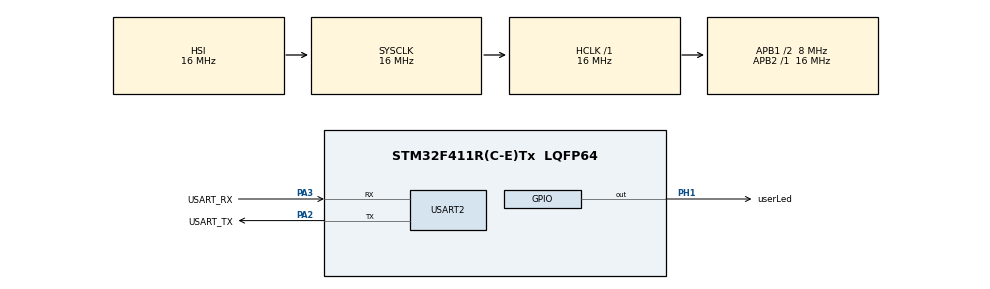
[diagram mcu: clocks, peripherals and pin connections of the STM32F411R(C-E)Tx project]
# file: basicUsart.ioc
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Mcu.Family=STM32F4
Mcu.Name=STM32F411R(C-E)Tx
Mcu.Package=LQFP64
NVIC.PriorityGroup=NVIC_PRIORITYGROUP_0
NVIC.TIM2_IRQn=true\:0\:0\:false\:false\:true\:true\:true\:true
NVIC.USART2_IRQn=true\:0\:0\:false\:false\:true\:true\:true\:true
PA13.GPIO_Label=TMS
PA13.Mode=Serial_Wire
PA13.Signal=SYS_JTMS-SWDIO
PA14.GPIO_Label=TCK
PA14.Mode=Serial_Wire
PA14.Signal=SYS_JTCK-SWCLK
PA2.GPIO_Label=USART_TX
PA2.Mode=Asynchronous
PA2.Signal=USART2_TX
PA3.GPIO_Label=USART_RX
PA3.Mode=Asynchronous
PA3.Signal=USART2_RX
PB3.GPIO_Label=SWO
PB3.Signal=SYS_JTDO-SWO
PH1\ -\ OSC_OUT.GPIO_Label=userLed
PH1\ -\ OSC_OUT.PinState=GPIO_PIN_SET
PH1\ -\ OSC_OUT.Signal=GPIO_Output
ProjectManager.HeapSize=0x200
ProjectManager.StackSize=0x400
ProjectManager.TargetToolchain=STM32CubeIDE
RCC.48MHZClocksFreq_Value=84000000
RCC.AHBFreq_Value=16000000
RCC.APB1CLKDivider=RCC_HCLK_DIV2
RCC.APB1Freq_Value=8000000
RCC.APB1TimFreq_Value=16000000
RCC.APB2Freq_Value=16000000
RCC.APB2TimFreq_Value=16000000
RCC.CortexFreq_Value=16000000
RCC.FLatency-AdvancedSettings=FLASH_LATENCY_0
RCC.HCLKFreq_Value=16000000
RCC.HSE_VALUE=8000000
RCC.HSI_VALUE=16000000
RCC.LSE_VALUE=32768
RCC.PLLN=336
RCC.PLLP=RCC_PLLP_DIV4
RCC.SYSCLKFreq_VALUE=16000000
RCC.VCOOutputFreq_Value=336000000
TIM2.Period=500-1
TIM2.Prescaler=16000-1
USART2.VirtualMode=VM_ASYNC
VP_TIM2_VS_ClockSourceINT.Mode=Internal
board=NUCLEO-F411RE

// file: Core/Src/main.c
/* USER CODE BEGIN Header */
/**
  ******************************************************************************
  * @file           : main.c
  * @brief          : Main program body
  ******************************************************************************
  * @attention
  *
  * Copyright (c) 2025 STMicroelectronics.
  * All rights reserved.
  *
  * This software is licensed under terms that can be found in the LICENSE file
  * in the root directory of this software component.
  * If no LICENSE file comes with this software, it is provided AS-IS.
  *
  ******************************************************************************
  */
/* USER CODE END Header */
#include "main.h"

/* USER CODE BEGIN Includes */
#include "stdint.h"
#include "stdio.h"
#include "string.h"
/* USER CODE END Includes */

TIM_HandleTypeDef htim2;

UART_HandleTypeDef huart2;

void SystemClock_Config(void);
static void MX_GPIO_Init(void);
static void MX_USART2_UART_Init(void);
static void MX_TIM2_Init(void);
/* USER CODE BEGIN PFP */
uint8_t contador = 0;
uint8_t bufferMsg[128] = {0};
uint8_t rx_buffer[100];
uint8_t rx_index = 0;
uint8_t rx_char = 0;
volatile uint8_t usart_flag = 0 ;
/* USER CODE END PFP */

int main(void)
{

  /* MCU Configuration--------------------------------------------------------*/

  /* Reset of all peripherals, Initializes the Flash interface and the Systick. */
  HAL_Init();

  /* Configure the system clock */
  SystemClock_Config();

  /* Initialize all configured peripherals */
  MX_GPIO_Init();
  MX_USART2_UART_Init();
  MX_TIM2_Init();
  /* USER CODE BEGIN 2 */
  HAL_TIM_Base_Start_IT(&htim2);
  HAL_UART_Receive_IT(&huart2,&rx_char,1);
  /* USER CODE END 2 */

  /* Infinite loop */
  /* USER CODE BEGIN WHILE */

  sprintf((char *)bufferMsg,"Prueba de sonido %u!! '\n'",contador);
  HAL_UART_Transmit(&huart2,bufferMsg,strlen((char *)bufferMsg),1000);
  __NOP();
  while (1)
  {
    /* USER CODE END WHILE */
	  if (usart_flag) {
		  sprintf((char *)bufferMsg,"Comando recibido %s\n",rx_buffer);
		  HAL_UART_Transmit(&huart2,bufferMsg,strlen((char * )bufferMsg),1000);
	      if (strncmp((char*)rx_buffer,"led=",4)==0){
	    	  int nuevo_delay = atoi((char*)&rx_buffer[4]);
	    	  __HAL_TIM_SET_AUTORELOAD(&htim2,nuevo_delay);
	          __HAL_TIM_SET_COUNTER(&htim2, 0);
	      }
	      // 4. ¡Limpio el buffer para el próximo comando!
	      memset(rx_buffer,0,sizeof(rx_buffer));

	      // 5. Bajo la bandera y sigo
	      usart_flag = 0;
	      }

  }
}

void SystemClock_Config(void)
{
  RCC_OscInitTypeDef RCC_OscInitStruct = {0};
  RCC_ClkInitTypeDef RCC_ClkInitStruct = {0};

  /** Configure the main internal regulator output voltage
  */
  __HAL_RCC_PWR_CLK_ENABLE();
  __HAL_PWR_VOLTAGESCALING_CONFIG(PWR_REGULATOR_VOLTAGE_SCALE1);

  /** Initializes the RCC Oscillators according to the specified parameters
  * in the RCC_OscInitTypeDef structure.
  */
  RCC_OscInitStruct.OscillatorType = RCC_OSCILLATORTYPE_HSI;
  RCC_OscInitStruct.HSIState = RCC_HSI_ON;
  RCC_OscInitStruct.HSICalibrationValue = RCC_HSICALIBRATION_DEFAULT;
  RCC_OscInitStruct.PLL.PLLState = RCC_PLL_NONE;
  if (HAL_RCC_OscConfig(&RCC_OscInitStruct) != HAL_OK)
  {
    Error_Handler();
  }

  /** Initializes the CPU, AHB and APB buses clocks
  */
  RCC_ClkInitStruct.ClockType = RCC_CLOCKTYPE_HCLK|RCC_CLOCKTYPE_SYSCLK
                              |RCC_CLOCKTYPE_PCLK1|RCC_CLOCKTYPE_PCLK2;
  RCC_ClkInitStruct.SYSCLKSource = RCC_SYSCLKSOURCE_HSI;
  RCC_ClkInitStruct.AHBCLKDivider = RCC_SYSCLK_DIV1;
  RCC_ClkInitStruct.APB1CLKDivider = RCC_HCLK_DIV2;
  RCC_ClkInitStruct.APB2CLKDivider = RCC_HCLK_DIV1;

  if (HAL_RCC_ClockConfig(&RCC_ClkInitStruct, FLASH_LATENCY_0) != HAL_OK)
  {
    Error_Handler();
  }
}

static void MX_TIM2_Init(void)
{

  TIM_ClockConfigTypeDef sClockSourceConfig = {0};
  TIM_MasterConfigTypeDef sMasterConfig = {0};

  htim2.Instance = TIM2;
  htim2.Init.Prescaler = 16000-1;
  htim2.Init.CounterMode = TIM_COUNTERMODE_UP;
  htim2.Init.Period = 500-1;
  htim2.Init.ClockDivision = TIM_CLOCKDIVISION_DIV1;
  htim2.Init.AutoReloadPreload = TIM_AUTORELOAD_PRELOAD_DISABLE;
  if (HAL_TIM_Base_Init(&htim2) != HAL_OK)
  {
    Error_Handler();
  }
  sClockSourceConfig.ClockSource = TIM_CLOCKSOURCE_INTERNAL;
  if (HAL_TIM_ConfigClockSource(&htim2, &sClockSourceConfig) != HAL_OK)
  {
    Error_Handler();
  }
  sMasterConfig.MasterOutputTrigger = TIM_TRGO_RESET;
  sMasterConfig.MasterSlaveMode = TIM_MASTERSLAVEMODE_DISABLE;
  if (HAL_TIMEx_MasterConfigSynchronization(&htim2, &sMasterConfig) != HAL_OK)
  {
    Error_Handler();
  }

}

static void MX_USART2_UART_Init(void)
{

  huart2.Instance = USART2;
  huart2.Init.BaudRate = 115200;
  huart2.Init.WordLength = UART_WORDLENGTH_8B;
  huart2.Init.StopBits = UART_STOPBITS_1;
  huart2.Init.Parity = UART_PARITY_NONE;
  huart2.Init.Mode = UART_MODE_TX_RX;
  huart2.Init.HwFlowCtl = UART_HWCONTROL_NONE;
  huart2.Init.OverSampling = UART_OVERSAMPLING_16;
  if (HAL_UART_Init(&huart2) != HAL_OK)
  {
    Error_Handler();
  }

}

static void MX_GPIO_Init(void)
{
  GPIO_InitTypeDef GPIO_InitStruct = {0};

  /* GPIO Ports Clock Enable */
  __HAL_RCC_GPIOH_CLK_ENABLE();
  __HAL_RCC_GPIOA_CLK_ENABLE();
  __HAL_RCC_GPIOB_CLK_ENABLE();

  /*Configure GPIO pin Output Level */
  HAL_GPIO_WritePin(userLed_GPIO_Port, userLed_Pin, GPIO_PIN_SET);

  /*Configure GPIO pin : userLed_Pin */
  GPIO_InitStruct.Pin = userLed_Pin;
  GPIO_InitStruct.Mode = GPIO_MODE_OUTPUT_PP;
  GPIO_InitStruct.Pull = GPIO_NOPULL;
  GPIO_InitStruct.Speed = GPIO_SPEED_FREQ_LOW;
  HAL_GPIO_Init(userLed_GPIO_Port, &GPIO_InitStruct);

}

/* USER CODE BEGIN 4 */
void HAL_TIM_PeriodElapsedCallback(TIM_HandleTypeDef *htim){
	if(htim->Instance==TIM2){
		HAL_GPIO_TogglePin(userLed_GPIO_Port,userLed_Pin);
	}
}
void HAL_UART_RxCpltCallback(UART_HandleTypeDef *huart){
	if (huart->Instance == USART2) {
	    // Si se recibe un byte, lo añadimos al buffer
	    if (rx_index < sizeof(rx_buffer) - 1) {
	      rx_buffer[rx_index++] = rx_char;  // Guardar el byte recibido
	    }

	    // Si se recibe el carácter '@', significa que el comando está completo
	    if (rx_char == '@') {
            usart_flag = 1;            // Marcar comando completo
            rx_buffer[rx_index] = '\0';// Cerrar string
            rx_index = 0;              // Preparar índice para el siguiente comando
	    }
	    HAL_UART_Receive_IT(huart, &rx_char, 1);
	    }
}
/* USER CODE END 4 */

void Error_Handler(void)
{
  __disable_irq();
  while (1)
  {
  }
}
